AUTOSAR XML (schema 4-0-3)
package /ComponentTypes
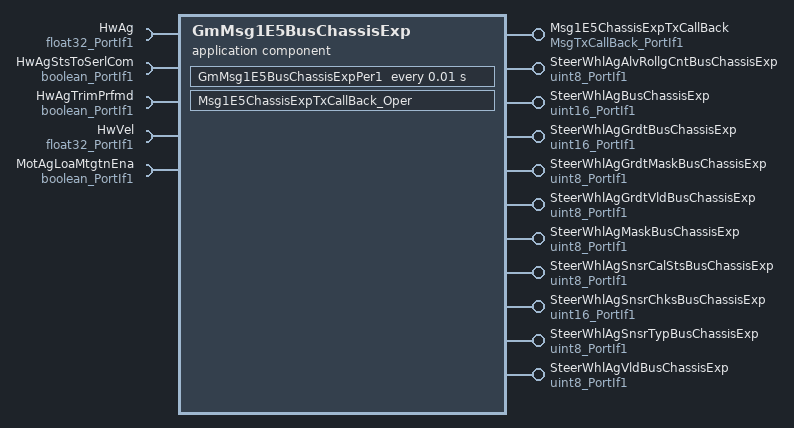
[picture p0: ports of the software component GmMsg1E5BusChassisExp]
  application sw component type GmMsg1E5BusChassisExp
    11 x provide port:
      Msg1E5ChassisExpTxCallBack: server-com-spec{operation=Oper, queue-length=1}, provided-interface=MsgTxCallBack_PortIf1
      SteerWhlAgAlvRollgCntBusChassisExp: nonqueued-sender-com-spec{data-element=Val, init-value=0}, provided-interface=uint8_PortIf1
      SteerWhlAgBusChassisExp: nonqueued-sender-com-spec{data-element=Val, init-value=0}, provided-interface=uint16_PortIf1
      SteerWhlAgGrdtBusChassisExp: nonqueued-sender-com-spec{data-element=Val, init-value=0}, provided-interface=uint16_PortIf1
      SteerWhlAgGrdtMaskBusChassisExp: nonqueued-sender-com-spec{data-element=Val, init-value=0}, provided-interface=uint8_PortIf1
      SteerWhlAgGrdtVldBusChassisExp: nonqueued-sender-com-spec{data-element=Val, init-value=0}, provided-interface=uint8_PortIf1
      SteerWhlAgMaskBusChassisExp: nonqueued-sender-com-spec{data-element=Val, init-value=0}, provided-interface=uint8_PortIf1
      SteerWhlAgSnsrCalStsBusChassisExp: nonqueued-sender-com-spec{data-element=Val, init-value=0}, provided-interface=uint8_PortIf1
      SteerWhlAgSnsrChksBusChassisExp: nonqueued-sender-com-spec{data-element=Val, init-value=0}, provided-interface=uint16_PortIf1
      SteerWhlAgSnsrTypBusChassisExp: nonqueued-sender-com-spec{data-element=Val, init-value=0}, provided-interface=uint8_PortIf1
      SteerWhlAgVldBusChassisExp: nonqueued-sender-com-spec{data-element=Val, init-value=0}, provided-interface=uint8_PortIf1
    5 x require port:
      HwAg: nonqueued-receiver-com-spec{data-element=Val, filter=data-filter-type=ALWAYS, init-value=0}, required-interface=float32_PortIf1
      HwAgStsToSerlCom: nonqueued-receiver-com-spec{data-element=Logl, filter=data-filter-type=ALWAYS, init-value=0}, required-interface=boolean_PortIf1
      HwAgTrimPrfmd: nonqueued-receiver-com-spec{data-element=Logl, filter=data-filter-type=ALWAYS, init-value=0}, required-interface=boolean_PortIf1
      HwVel: nonqueued-receiver-com-spec{data-element=Val, filter=data-filter-type=ALWAYS, init-value=0}, required-interface=float32_PortIf1
      MotAgLoaMtgtnEna: nonqueued-receiver-com-spec{data-element=Logl, filter=data-filter-type=ALWAYS, init-value=0}, required-interface=boolean_PortIf1
    behavior GmMsg1E5BusChassisExp_InternalBehavior: data-type-mapping=Nexteer
      ar-typed-per-instance-memorys:
        data GmMsg1E5BusChassisExpRollgCntr: sw-calibration-access=READ-ONLY, type=uint8
      timing event TMT_GM0C9HSPer1: start-on-event=GmMsg1E5BusChassisExpPer1, period=0.01
      operation invoked event OIT_Msg1E5ChassisExpTxCallBack_Oper_Msg1E5ChassisExpTxCallBack_Oper: start-on-event=Msg1E5ChassisExpTxCallBack_Oper, operation=Msg1E5ChassisExpTxCallBack.Oper
      runnable GmMsg1E5BusChassisExpPer1
        data-receive-point-by-arguments:
          5 x access:
            REC_HwAg_Val: accessed-variable=HwAg.Val
            REC_HwAgCalCmpl_Logl: accessed-variable=HwAgTrimPrfmd.Logl
            REC_HwAgVld_Logl: accessed-variable=HwAgStsToSerlCom.Logl
            REC_HwVel_Val: accessed-variable=HwVel.Val
            REC_MotAgLoaMtgtnEna_Logl: accessed-variable=MotAgLoaMtgtnEna.Logl
        data-send-points:
          10 x access:
            SEND_GM1E5HSSteerWhlAg_Val: accessed-variable=SteerWhlAgBusChassisExp.Val
            SEND_GM1E5HSSteerWhlAgAlvRollgCnt_Val: accessed-variable=SteerWhlAgAlvRollgCntBusChassisExp.Val
            SEND_GM1E5HSSteerWhlAgGrdt_Val: accessed-variable=SteerWhlAgGrdtBusChassisExp.Val
            SEND_GM1E5HSSteerWhlAgGrdtMask_Val: accessed-variable=SteerWhlAgGrdtMaskBusChassisExp.Val
            SEND_GM1E5HSSteerWhlAgGrdtVld_Val: accessed-variable=SteerWhlAgGrdtVldBusChassisExp.Val
            SEND_GM1E5HSSteerWhlAgMask_Val: accessed-variable=SteerWhlAgMaskBusChassisExp.Val
            SEND_GM1E5HSSteerWhlAgSnsrCalSts_Val: accessed-variable=SteerWhlAgSnsrCalStsBusChassisExp.Val
            SEND_GM1E5HSSteerWhlAgSnsrChks_Val: accessed-variable=SteerWhlAgSnsrChksBusChassisExp.Val
            SEND_GM1E5HSSteerWhlAgSnsrTyp_Val: accessed-variable=SteerWhlAgSnsrTypBusChassisExp.Val
            SEND_GM1E5HSSteerWhlAgVld_Val: accessed-variable=SteerWhlAgVldBusChassisExp.Val
      runnable Msg1E5ChassisExpTxCallBack_Oper
  swc implementation GmMsg1E5BusChassisExp_Implementation: behavior=GmMsg1E5BusChassisExp_InternalBehavior
    code-descriptors:
      code Default: artifact-descriptors=autosar-engineering-object={short-label=Default, category=SWSRC}
